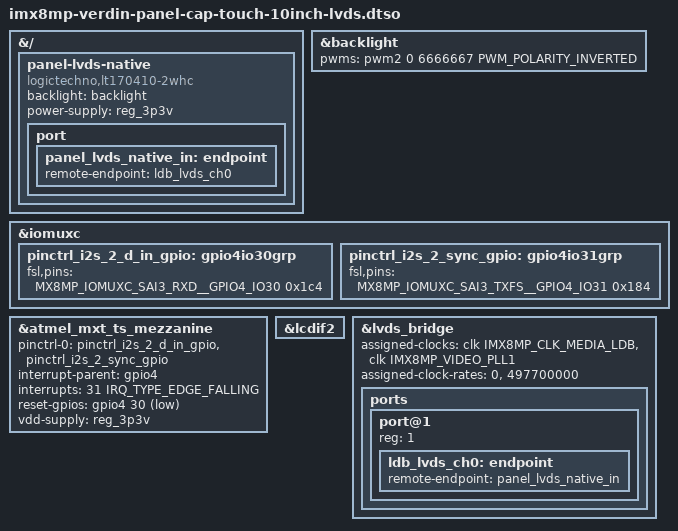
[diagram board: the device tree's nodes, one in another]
// SPDX-License-Identifier: GPL-2.0-or-later OR MIT
/*
 * Copyright (c) Toradex
 *
 * Toradex Capacitive Touch Display 10.1" connected via Verdin iMX8M Plus LCDIF
 * on carrier boards with a Toradex standard LVDS display connector
 * (e.g., Mallow).
 *
 * https://developer.toradex.com/hardware/accessories/displays/capacitive-touch-display-101inch-lvds
 * https://www.toradex.com/accessories/capacitive-touch-display-10.1-inch-lvds
 */

/dts-v1/;
/plugin/;

#include <dt-bindings/clock/imx8mp-clock.h>
#include <dt-bindings/gpio/gpio.h>
#include <dt-bindings/interrupt-controller/irq.h>
#include <dt-bindings/pwm/pwm.h>

#include "imx8mp-pinfunc.h"

&{/} {
	panel-lvds-native {
		compatible = "logictechno,lt170410-2whc";
		backlight = <&backlight>;
		power-supply = <&reg_3p3v>;

		port {
			panel_lvds_native_in: endpoint {
				remote-endpoint = <&ldb_lvds_ch0>;
			};
		};
	};
};

&backlight {
	/* Verdin PWM_2 (SODIMM 16) */
	pwms = <&pwm2 0 6666667 PWM_POLARITY_INVERTED>;

	status = "okay";
};

&iomuxc {
	pinctrl_i2s_2_d_in_gpio: gpio4io30grp {
		fsl,pins = <MX8MP_IOMUXC_SAI3_RXD__GPIO4_IO30 0x1c4>;	/* SODIMM 48 */
	};

	pinctrl_i2s_2_sync_gpio: gpio4io31grp {
		fsl,pins = <MX8MP_IOMUXC_SAI3_TXFS__GPIO4_IO31 0x184>;	/* SODIMM 44 */
	};
};

&atmel_mxt_ts_mezzanine {
	pinctrl-names = "default";
	pinctrl-0 = <&pinctrl_i2s_2_d_in_gpio>, <&pinctrl_i2s_2_sync_gpio>;
	/* Verdin I2S_2_SYNC as GPIO (SODIMM 44) */
	interrupt-parent = <&gpio4>;
	interrupts = <31 IRQ_TYPE_EDGE_FALLING>;
	/* Verdin I2S_2_D_IN as GPIO (SODIMM 48) */
	reset-gpios = <&gpio4 30 GPIO_ACTIVE_LOW>;
	vdd-supply = <&reg_3p3v>;

	status = "okay";
};

&lcdif2 {
	status = "okay";
};

&lvds_bridge {
	assigned-clocks = <&clk IMX8MP_CLK_MEDIA_LDB>,
			  <&clk IMX8MP_VIDEO_PLL1>;
	/*
	 * This display uses 71.1 MHz pixel clock, so IMX8MP_VIDEO_PLL1 needs
	 * to be 7 times 71.1MHz, or 497.7 MHz as the internal divider will
	 * always divide the output LVDS clock by 7.
	 */
	assigned-clock-rates = <0>, <497700000>;

	status = "okay";

	ports {
		#address-cells = <1>;
		#size-cells = <0>;

		port@1 {
			reg = <1>;

			ldb_lvds_ch0: endpoint {
				remote-endpoint = <&panel_lvds_native_in>;
			};
		};
	};
};
